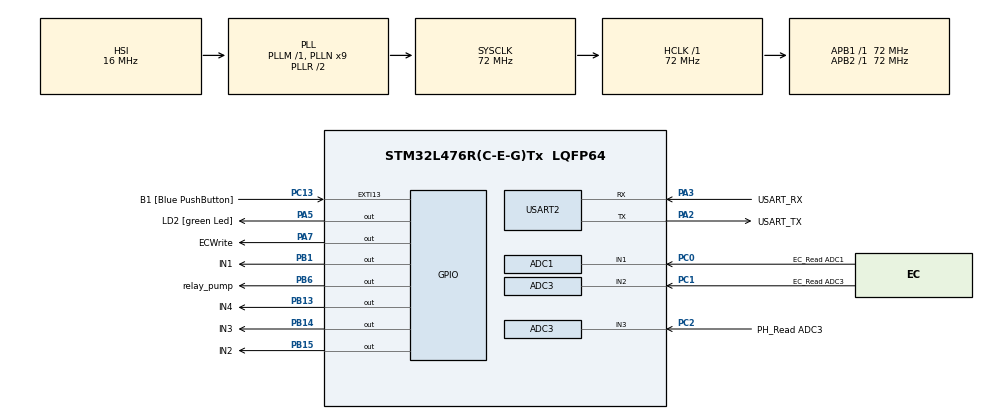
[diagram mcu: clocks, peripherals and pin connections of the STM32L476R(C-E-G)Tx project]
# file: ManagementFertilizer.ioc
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ADC1.Channel-0\#ChannelRegularConversion=ADC_CHANNEL_1
ADC1.ClockPrescaler=ADC_CLOCK_ASYNC_DIV4
ADC1.EOCSelection=ADC_EOC_SEQ_CONV
ADC1.NbrOfConversionFlag=1
ADC1.OffsetNumber-0\#ChannelRegularConversion=ADC_OFFSET_NONE
ADC1.Rank-0\#ChannelRegularConversion=1
ADC1.Resolution=ADC_RESOLUTION_10B
ADC1.SamplingTime-0\#ChannelRegularConversion=ADC_SAMPLETIME_2CYCLES_5
ADC1.master=1
ADC3.Channel-2\#ChannelRegularConversion=ADC_CHANNEL_2
ADC3.ClockPrescaler=ADC_CLOCK_ASYNC_DIV4
ADC3.EOCSelection=ADC_EOC_SEQ_CONV
ADC3.NbrOfConversionFlag=1
ADC3.OffsetNumber-2\#ChannelRegularConversion=ADC_OFFSET_NONE
ADC3.Rank-2\#ChannelRegularConversion=1
ADC3.Resolution=ADC_RESOLUTION_10B
ADC3.SamplingTime-2\#ChannelRegularConversion=ADC_SAMPLETIME_2CYCLES_5
Mcu.Family=STM32L4
Mcu.Name=STM32L476R(C-E-G)Tx
Mcu.Package=LQFP64
NVIC.PriorityGroup=NVIC_PRIORITYGROUP_4
PA13\ (JTMS-SWDIO).GPIO_Label=TMS
PA13\ (JTMS-SWDIO).Mode=Serial_Wire
PA13\ (JTMS-SWDIO).Signal=SYS_JTMS-SWDIO
PA14\ (JTCK-SWCLK).GPIO_Label=TCK
PA14\ (JTCK-SWCLK).Mode=Serial_Wire
PA14\ (JTCK-SWCLK).Signal=SYS_JTCK-SWCLK
PA2.GPIO_Label=USART_TX
PA2.GPIO_Mode=GPIO_MODE_AF_PP
PA2.GPIO_PuPd=GPIO_NOPULL
PA2.GPIO_Speed=GPIO_SPEED_FREQ_VERY_HIGH
PA2.Mode=Asynchronous
PA2.Signal=USART2_TX
PA3.GPIO_Label=USART_RX
PA3.GPIO_Mode=GPIO_MODE_AF_PP
PA3.GPIO_PuPd=GPIO_NOPULL
PA3.GPIO_Speed=GPIO_SPEED_FREQ_VERY_HIGH
PA3.Mode=Asynchronous
PA3.Signal=USART2_RX
PA5.GPIO_Label=LD2 [green Led]
PA5.GPIO_ModeDefaultOutputPP=GPIO_MODE_OUTPUT_PP
PA5.GPIO_PuPd=GPIO_NOPULL
PA5.GPIO_Speed=GPIO_SPEED_FREQ_LOW
PA5.Signal=GPIO_Output
PA7.GPIO_Label=ECWrite
PA7.Signal=GPIO_Output
PB1.GPIO_Label=IN1
PB1.Signal=GPIO_Output
PB13.GPIO_Label=IN4
PB13.Signal=GPIO_Output
PB14.GPIO_Label=IN3
PB14.Signal=GPIO_Output
PB15.GPIO_Label=IN2
PB15.Signal=GPIO_Output
PB3\ (JTDO-TRACESWO).GPIO_Label=SWO
PB3\ (JTDO-TRACESWO).Signal=SYS_JTDO-SWO
PB6.GPIO_Label=relay_pump
PB6.Signal=GPIO_Output
PC0.GPIO_Label=EC_Read ADC1
PC0.Signal=ADCx_IN1
PC1.GPIO_Label=EC_Read ADC3
PC1.Signal=ADCx_IN2
PC13.GPIO_Label=B1 [Blue PushButton]
PC13.GPIO_ModeDefaultEXTI=GPIO_MODE_IT_FALLING
PC13.GPIO_PuPd=GPIO_NOPULL
PC13.Signal=GPXTI13
PC14-OSC32_IN\ (PC14).Mode=LSE-External-Oscillator
PC14-OSC32_IN\ (PC14).Signal=RCC_OSC32_IN
PC15-OSC32_OUT\ (PC15).Mode=LSE-External-Oscillator
PC15-OSC32_OUT\ (PC15).Signal=RCC_OSC32_OUT
PC2.GPIO_Label=PH_Read ADC3
PC2.Signal=ADCx_IN3
PH0-OSC_IN\ (PH0).Signal=RCC_OSC_IN
PH1-OSC_OUT\ (PH1).Signal=RCC_OSC_OUT
ProjectManager.HeapSize=0x200
ProjectManager.StackSize=0x400
ProjectManager.TargetToolchain=STM32CubeIDE
RCC.ADCFreq_Value=64000000
RCC.AHBFreq_Value=72000000
RCC.APB1Freq_Value=72000000
RCC.APB1TimFreq_Value=72000000
RCC.APB2Freq_Value=72000000
RCC.APB2TimFreq_Value=72000000
RCC.CortexFreq_Value=72000000
RCC.HCLKFreq_Value=72000000
RCC.HSE_VALUE=8000000
RCC.HSI_VALUE=16000000
RCC.MSI_VALUE=4000000
RCC.PLLN=9
RCC.PLLSourceVirtual=RCC_PLLSOURCE_HSI
RCC.PREFETCH_ENABLE=1
RCC.SYSCLKFreq_VALUE=72000000
RCC.SYSCLKSource=RCC_SYSCLKSOURCE_PLLCLK
RCC.USBFreq_Value=64000000
RCC.VCOOutputFreq_Value=144000000
SH.ADCx_IN1.0=ADC1_IN1,IN1-Single-Ended
SH.ADCx_IN2.0=ADC3_IN2,IN2-Single-Ended
SH.ADCx_IN3.0=ADC3_IN3,IN3-Single-Ended
TIM2.Period=10000
TIM2.Prescaler=7200-1
USART2.VirtualMode-Asynchronous=VM_ASYNC
VP_TIM2_VS_ClockSourceINT.Mode=Internal
board=NUCLEO-L476RG

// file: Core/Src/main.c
/* USER CODE BEGIN Header */
/**
  ******************************************************************************
  * @file           : main.c
  * @brief          : Main program body
  ******************************************************************************
  * @attention
  *
  * Copyright (c) 2023 STMicroelectronics.
  * All rights reserved.
  *
  * This software is licensed under terms that can be found in the LICENSE file
  * in the root directory of this software component.
  * If no LICENSE file comes with this software, it is provided AS-IS.
  *
  ******************************************************************************
  */
/* USER CODE END Header */
#include "main.h"
#include "adc.h"
#include "tim.h"
#include "usart.h"
#include "gpio.h"

/* USER CODE BEGIN Includes */
#include "ec_ph_main.h"
#include "step_main.h"
#include "relay_pump.h"
/* USER CODE END Includes */

void SystemClock_Config(void);
void PeriphCommonClock_Config(void);

int main(void)
{

  /* MCU Configuration--------------------------------------------------------*/

  /* Reset of all peripherals, Initializes the Flash interface and the Systick. */
  HAL_Init();

  /* Configure the system clock */
  SystemClock_Config();

/* Configure the peripherals common clocks */
  PeriphCommonClock_Config();

  /* Initialize all configured peripherals */
  MX_GPIO_Init();
  MX_USART2_UART_Init();
  MX_ADC3_Init();
  MX_TIM2_Init();
  MX_ADC1_Init();

  /* Infinite loop */
  /* USER CODE BEGIN WHILE */
//    int angle = 360;
// 	int rotation = 0;
// 	int rpm = 10;
//
// 	float ec_setpoint = 50;

  while (1)
  {
	  ec_read();
	  ph_read();

    /* USER CODE END WHILE */

    /* USER CODE BEGIN 3 */

//	  if (ec_read() < ec_setpoint)
//	  	   {
//	  		   stepper_step_angle(angle, rotation, rpm); // Setup angolo, senso di rotazione, velocità rpm
//	  		   pump_control();
//	  	   }
//
//	  ph_read();

  }
  /* USER CODE END 3 */
}

void SystemClock_Config(void)
{
  RCC_OscInitTypeDef RCC_OscInitStruct = {0};
  RCC_ClkInitTypeDef RCC_ClkInitStruct = {0};

  /** Configure the main internal regulator output voltage
  */
  if (HAL_PWREx_ControlVoltageScaling(PWR_REGULATOR_VOLTAGE_SCALE1) != HAL_OK)
  {
    Error_Handler();
  }

  /** Initializes the RCC Oscillators according to the specified parameters
  * in the RCC_OscInitTypeDef structure.
  */
  RCC_OscInitStruct.OscillatorType = RCC_OSCILLATORTYPE_HSI;
  RCC_OscInitStruct.HSIState = RCC_HSI_ON;
  RCC_OscInitStruct.HSICalibrationValue = RCC_HSICALIBRATION_DEFAULT;
  RCC_OscInitStruct.PLL.PLLState = RCC_PLL_ON;
  RCC_OscInitStruct.PLL.PLLSource = RCC_PLLSOURCE_HSI;
  RCC_OscInitStruct.PLL.PLLM = 1;
  RCC_OscInitStruct.PLL.PLLN = 9;
  RCC_OscInitStruct.PLL.PLLP = RCC_PLLP_DIV7;
  RCC_OscInitStruct.PLL.PLLQ = RCC_PLLQ_DIV2;
  RCC_OscInitStruct.PLL.PLLR = RCC_PLLR_DIV2;
  if (HAL_RCC_OscConfig(&RCC_OscInitStruct) != HAL_OK)
  {
    Error_Handler();
  }

  /** Initializes the CPU, AHB and APB buses clocks
  */
  RCC_ClkInitStruct.ClockType = RCC_CLOCKTYPE_HCLK|RCC_CLOCKTYPE_SYSCLK
                              |RCC_CLOCKTYPE_PCLK1|RCC_CLOCKTYPE_PCLK2;
  RCC_ClkInitStruct.SYSCLKSource = RCC_SYSCLKSOURCE_PLLCLK;
  RCC_ClkInitStruct.AHBCLKDivider = RCC_SYSCLK_DIV1;
  RCC_ClkInitStruct.APB1CLKDivider = RCC_HCLK_DIV1;
  RCC_ClkInitStruct.APB2CLKDivider = RCC_HCLK_DIV1;

  if (HAL_RCC_ClockConfig(&RCC_ClkInitStruct, FLASH_LATENCY_4) != HAL_OK)
  {
    Error_Handler();
  }
}

void PeriphCommonClock_Config(void)
{
  RCC_PeriphCLKInitTypeDef PeriphClkInit = {0};

  /** Initializes the peripherals clock
  */
  PeriphClkInit.PeriphClockSelection = RCC_PERIPHCLK_ADC;
  PeriphClkInit.AdcClockSelection = RCC_ADCCLKSOURCE_PLLSAI1;
  PeriphClkInit.PLLSAI1.PLLSAI1Source = RCC_PLLSOURCE_HSI;
  PeriphClkInit.PLLSAI1.PLLSAI1M = 1;
  PeriphClkInit.PLLSAI1.PLLSAI1N = 8;
  PeriphClkInit.PLLSAI1.PLLSAI1P = RCC_PLLP_DIV7;
  PeriphClkInit.PLLSAI1.PLLSAI1Q = RCC_PLLQ_DIV2;
  PeriphClkInit.PLLSAI1.PLLSAI1R = RCC_PLLR_DIV2;
  PeriphClkInit.PLLSAI1.PLLSAI1ClockOut = RCC_PLLSAI1_ADC1CLK;
  if (HAL_RCCEx_PeriphCLKConfig(&PeriphClkInit) != HAL_OK)
  {
    Error_Handler();
  }
}

void Error_Handler(void)
{
  __disable_irq();
  while (1)
  {
  }
}
